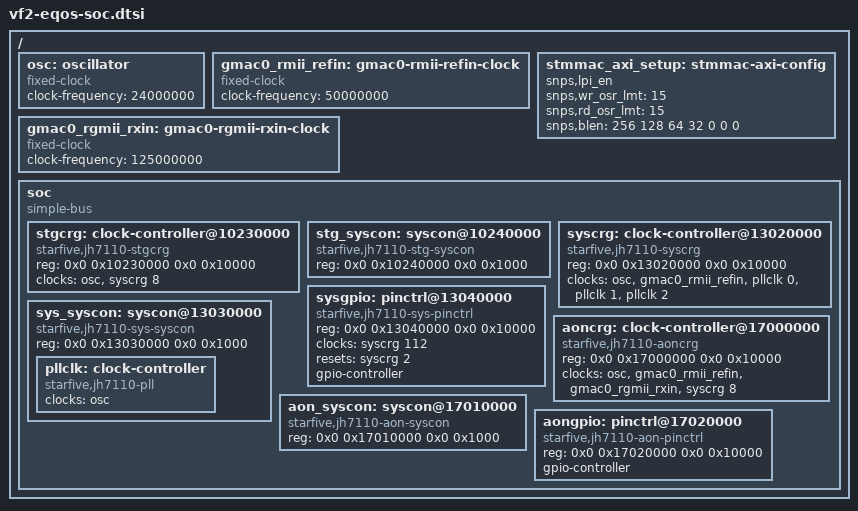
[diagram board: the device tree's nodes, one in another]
/*
 * The SoC part of a device tree in the shape of the VisionFive 2's
 * (Linux v6.12 jh7110.dtsi and jh7110-common.dtsi) for the Ethernet
 * glue's checks: the clock generators, system control blocks, pin
 * controllers and the AXI settings the first port's node refers to.
 * The port itself is in the two board versions' files.
 */

/ {
	#address-cells = <2>;
	#size-cells = <2>;

	osc: oscillator {
		compatible = "fixed-clock";
		#clock-cells = <0>;
		clock-frequency = <24000000>;
	};

	gmac0_rmii_refin: gmac0-rmii-refin-clock {
		compatible = "fixed-clock";
		#clock-cells = <0>;
		clock-frequency = <50000000>;
	};

	stmmac_axi_setup: stmmac-axi-config {
		snps,lpi_en;
		snps,wr_osr_lmt = <15>;
		snps,rd_osr_lmt = <15>;
		snps,blen = <256 128 64 32 0 0 0>;
	};

	gmac0_rgmii_rxin: gmac0-rgmii-rxin-clock {
		compatible = "fixed-clock";
		#clock-cells = <0>;
		clock-frequency = <125000000>;
	};

	soc: soc {
		compatible = "simple-bus";
		#address-cells = <2>;
		#size-cells = <2>;
		ranges;

		stgcrg: clock-controller@10230000 {
			compatible = "starfive,jh7110-stgcrg";
			reg = <0x0 0x10230000 0x0 0x10000>;
			clocks = <&osc>, <&syscrg 8>;
			clock-names = "osc", "stg_axiahb";
			#clock-cells = <1>;
			#reset-cells = <1>;
		};

		stg_syscon: syscon@10240000 {
			compatible = "starfive,jh7110-stg-syscon", "syscon";
			reg = <0x0 0x10240000 0x0 0x1000>;
		};

		syscrg: clock-controller@13020000 {
			compatible = "starfive,jh7110-syscrg";
			reg = <0x0 0x13020000 0x0 0x10000>;
			clocks = <&osc>, <&gmac0_rmii_refin>, <&pllclk 0>, <&pllclk 1>, <&pllclk 2>;
			clock-names = "osc", "gmac1_rmii_refin", "pll0_out", "pll1_out", "pll2_out";
			#clock-cells = <1>;
			#reset-cells = <1>;
		};

		sys_syscon: syscon@13030000 {
			compatible = "starfive,jh7110-sys-syscon", "syscon", "simple-mfd";
			reg = <0x0 0x13030000 0x0 0x1000>;

			pllclk: clock-controller {
				compatible = "starfive,jh7110-pll";
				clocks = <&osc>;
				#clock-cells = <1>;
			};
		};

		sysgpio: pinctrl@13040000 {
			compatible = "starfive,jh7110-sys-pinctrl";
			reg = <0x0 0x13040000 0x0 0x10000>;
			clocks = <&syscrg 112>;
			resets = <&syscrg 2>;
			gpio-controller;
			#gpio-cells = <2>;

		};




		aoncrg: clock-controller@17000000 {
			compatible = "starfive,jh7110-aoncrg";
			reg = <0x0 0x17000000 0x0 0x10000>;
			clocks = <&osc>, <&gmac0_rmii_refin>, <&gmac0_rgmii_rxin>, <&syscrg 8>;
			clock-names = "osc", "gmac0_rmii_refin", "gmac0_rgmii_rxin", "stg_axiahb";
			#clock-cells = <1>;
			#reset-cells = <1>;
		};

		aon_syscon: syscon@17010000 {
			compatible = "starfive,jh7110-aon-syscon", "syscon";
			reg = <0x0 0x17010000 0x0 0x1000>;
		};

		aongpio: pinctrl@17020000 {
			compatible = "starfive,jh7110-aon-pinctrl";
			reg = <0x0 0x17020000 0x0 0x10000>;
			gpio-controller;
			#gpio-cells = <2>;
		};
	};
};
